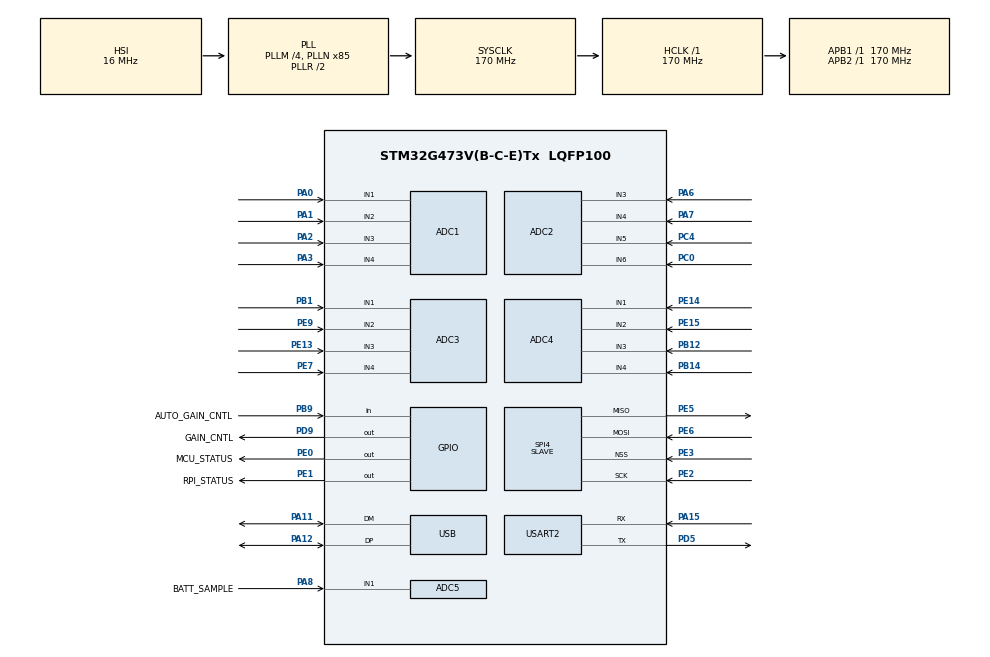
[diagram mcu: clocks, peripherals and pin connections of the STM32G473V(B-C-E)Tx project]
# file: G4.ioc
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ADC1.Channel-2\#ChannelRegularConversion=ADC_CHANNEL_1
ADC1.Channel-3\#ChannelRegularConversion=ADC_CHANNEL_2
ADC1.Channel-4\#ChannelRegularConversion=ADC_CHANNEL_3
ADC1.Channel-5\#ChannelRegularConversion=ADC_CHANNEL_4
ADC1.ContinuousConvMode=DISABLE
ADC1.DMAContinuousRequests=ENABLE
ADC1.ExternalTrigConv=ADC_EXTERNALTRIG_T6_TRGO
ADC1.NbrOfConversion=4
ADC1.NbrOfConversionFlag=1
ADC1.OffsetNumber-2\#ChannelRegularConversion=ADC_OFFSET_NONE
ADC1.OffsetNumber-3\#ChannelRegularConversion=ADC_OFFSET_NONE
ADC1.OffsetNumber-4\#ChannelRegularConversion=ADC_OFFSET_NONE
ADC1.OffsetNumber-5\#ChannelRegularConversion=ADC_OFFSET_NONE
ADC1.Overrun=ADC_OVR_DATA_OVERWRITTEN
ADC1.Rank-2\#ChannelRegularConversion=1
ADC1.Rank-3\#ChannelRegularConversion=2
ADC1.Rank-4\#ChannelRegularConversion=3
ADC1.Rank-5\#ChannelRegularConversion=4
ADC1.SamplingTime-2\#ChannelRegularConversion=ADC_SAMPLETIME_12CYCLES_5
ADC1.SamplingTime-3\#ChannelRegularConversion=ADC_SAMPLETIME_12CYCLES_5
ADC1.SamplingTime-4\#ChannelRegularConversion=ADC_SAMPLETIME_12CYCLES_5
ADC1.SamplingTime-5\#ChannelRegularConversion=ADC_SAMPLETIME_12CYCLES_5
ADC1.master=1
ADC2.Channel-0\#ChannelRegularConversion=ADC_CHANNEL_3
ADC2.Channel-1\#ChannelRegularConversion=ADC_CHANNEL_4
ADC2.Channel-2\#ChannelRegularConversion=ADC_CHANNEL_5
ADC2.Channel-3\#ChannelRegularConversion=ADC_CHANNEL_6
ADC2.ContinuousConvMode=DISABLE
ADC2.DMAContinuousRequests=ENABLE
ADC2.ExternalTrigConv=ADC_EXTERNALTRIG_T6_TRGO
ADC2.NbrOfConversion=4
ADC2.NbrOfConversionFlag=1
ADC2.OffsetNumber-0\#ChannelRegularConversion=ADC_OFFSET_NONE
ADC2.OffsetNumber-1\#ChannelRegularConversion=ADC_OFFSET_NONE
ADC2.OffsetNumber-2\#ChannelRegularConversion=ADC_OFFSET_NONE
ADC2.OffsetNumber-3\#ChannelRegularConversion=ADC_OFFSET_NONE
ADC2.Overrun=ADC_OVR_DATA_OVERWRITTEN
ADC2.Rank-0\#ChannelRegularConversion=1
ADC2.Rank-1\#ChannelRegularConversion=2
ADC2.Rank-2\#ChannelRegularConversion=3
ADC2.Rank-3\#ChannelRegularConversion=4
ADC2.SamplingTime-0\#ChannelRegularConversion=ADC_SAMPLETIME_12CYCLES_5
ADC2.SamplingTime-1\#ChannelRegularConversion=ADC_SAMPLETIME_12CYCLES_5
ADC2.SamplingTime-2\#ChannelRegularConversion=ADC_SAMPLETIME_12CYCLES_5
ADC2.SamplingTime-3\#ChannelRegularConversion=ADC_SAMPLETIME_12CYCLES_5
ADC3.Channel-0\#ChannelRegularConversion=ADC_CHANNEL_1
ADC3.Channel-1\#ChannelRegularConversion=ADC_CHANNEL_2
ADC3.Channel-2\#ChannelRegularConversion=ADC_CHANNEL_3
ADC3.Channel-3\#ChannelRegularConversion=ADC_CHANNEL_4
ADC3.ContinuousConvMode=DISABLE
ADC3.DMAContinuousRequests=ENABLE
ADC3.ExternalTrigConv=ADC_EXTERNALTRIG_T6_TRGO
ADC3.NbrOfConversion=4
ADC3.NbrOfConversionFlag=1
ADC3.OffsetNumber-0\#ChannelRegularConversion=ADC_OFFSET_NONE
ADC3.OffsetNumber-1\#ChannelRegularConversion=ADC_OFFSET_NONE
ADC3.OffsetNumber-2\#ChannelRegularConversion=ADC_OFFSET_NONE
ADC3.OffsetNumber-3\#ChannelRegularConversion=ADC_OFFSET_NONE
ADC3.Overrun=ADC_OVR_DATA_OVERWRITTEN
ADC3.Rank-0\#ChannelRegularConversion=1
ADC3.Rank-1\#ChannelRegularConversion=2
ADC3.Rank-2\#ChannelRegularConversion=3
ADC3.Rank-3\#ChannelRegularConversion=4
ADC3.SamplingTime-0\#ChannelRegularConversion=ADC_SAMPLETIME_12CYCLES_5
ADC3.SamplingTime-1\#ChannelRegularConversion=ADC_SAMPLETIME_12CYCLES_5
ADC3.SamplingTime-2\#ChannelRegularConversion=ADC_SAMPLETIME_12CYCLES_5
ADC3.SamplingTime-3\#ChannelRegularConversion=ADC_SAMPLETIME_12CYCLES_5
ADC3.master=1
ADC4.Channel-0\#ChannelRegularConversion=ADC_CHANNEL_1
ADC4.Channel-1\#ChannelRegularConversion=ADC_CHANNEL_2
ADC4.Channel-2\#ChannelRegularConversion=ADC_CHANNEL_3
ADC4.Channel-3\#ChannelRegularConversion=ADC_CHANNEL_4
ADC4.ContinuousConvMode=DISABLE
ADC4.DMAContinuousRequests=ENABLE
ADC4.EnableAnalogWatchDog1=false
ADC4.ExternalTrigConv=ADC_EXTERNALTRIG_T6_TRGO
ADC4.NbrOfConversion=4
ADC4.NbrOfConversionFlag=1
ADC4.OffsetNumber-0\#ChannelRegularConversion=ADC_OFFSET_NONE
ADC4.OffsetNumber-1\#ChannelRegularConversion=ADC_OFFSET_NONE
ADC4.OffsetNumber-2\#ChannelRegularConversion=ADC_OFFSET_NONE
ADC4.OffsetNumber-3\#ChannelRegularConversion=ADC_OFFSET_NONE
ADC4.Overrun=ADC_OVR_DATA_OVERWRITTEN
ADC4.Rank-0\#ChannelRegularConversion=1
ADC4.Rank-1\#ChannelRegularConversion=2
ADC4.Rank-2\#ChannelRegularConversion=3
ADC4.Rank-3\#ChannelRegularConversion=4
ADC4.SamplingTime-0\#ChannelRegularConversion=ADC_SAMPLETIME_12CYCLES_5
ADC4.SamplingTime-1\#ChannelRegularConversion=ADC_SAMPLETIME_12CYCLES_5
ADC4.SamplingTime-2\#ChannelRegularConversion=ADC_SAMPLETIME_12CYCLES_5
ADC4.SamplingTime-3\#ChannelRegularConversion=ADC_SAMPLETIME_12CYCLES_5
ADC5.Channel-4\#ChannelRegularConversion=ADC_CHANNEL_1
ADC5.NbrOfConversionFlag=1
ADC5.OffsetNumber-4\#ChannelRegularConversion=ADC_OFFSET_NONE
ADC5.Rank-4\#ChannelRegularConversion=1
ADC5.SamplingTime-4\#ChannelRegularConversion=ADC_SAMPLETIME_2CYCLES_5
Dma.ADC1.0.Direction=DMA_PERIPH_TO_MEMORY
Dma.ADC1.0.EventEnable=DISABLE
Dma.ADC1.0.Instance=DMA1_Channel1
Dma.ADC1.0.MemDataAlignment=DMA_MDATAALIGN_HALFWORD
Dma.ADC1.0.MemInc=DMA_MINC_ENABLE
Dma.ADC1.0.Mode=DMA_CIRCULAR
Dma.ADC1.0.PeriphDataAlignment=DMA_PDATAALIGN_HALFWORD
Dma.ADC1.0.PeriphInc=DMA_PINC_DISABLE
Dma.ADC1.0.Polarity=HAL_DMAMUX_REQ_GEN_RISING
Dma.ADC1.0.Priority=DMA_PRIORITY_LOW
Dma.ADC1.0.RequestNumber=1
Dma.ADC1.0.SignalID=NONE
Dma.ADC1.0.SyncEnable=DISABLE
Dma.ADC1.0.SyncPolarity=HAL_DMAMUX_SYNC_NO_EVENT
Dma.ADC1.0.SyncRequestNumber=1
Dma.ADC1.0.SyncSignalID=NONE
Dma.ADC2.1.Direction=DMA_PERIPH_TO_MEMORY
Dma.ADC2.1.EventEnable=DISABLE
Dma.ADC2.1.Instance=DMA1_Channel2
Dma.ADC2.1.MemDataAlignment=DMA_MDATAALIGN_HALFWORD
Dma.ADC2.1.MemInc=DMA_MINC_ENABLE
Dma.ADC2.1.Mode=DMA_CIRCULAR
Dma.ADC2.1.PeriphDataAlignment=DMA_PDATAALIGN_HALFWORD
Dma.ADC2.1.PeriphInc=DMA_PINC_DISABLE
Dma.ADC2.1.Polarity=HAL_DMAMUX_REQ_GEN_RISING
Dma.ADC2.1.Priority=DMA_PRIORITY_LOW
Dma.ADC2.1.RequestNumber=1
Dma.ADC2.1.SignalID=NONE
Dma.ADC2.1.SyncEnable=DISABLE
Dma.ADC2.1.SyncPolarity=HAL_DMAMUX_SYNC_NO_EVENT
Dma.ADC2.1.SyncRequestNumber=1
Dma.ADC2.1.SyncSignalID=NONE
Dma.ADC3.2.Direction=DMA_PERIPH_TO_MEMORY
Dma.ADC3.2.EventEnable=DISABLE
Dma.ADC3.2.Instance=DMA1_Channel3
Dma.ADC3.2.MemDataAlignment=DMA_MDATAALIGN_HALFWORD
Dma.ADC3.2.MemInc=DMA_MINC_ENABLE
Dma.ADC3.2.Mode=DMA_CIRCULAR
Dma.ADC3.2.PeriphDataAlignment=DMA_PDATAALIGN_HALFWORD
Dma.ADC3.2.PeriphInc=DMA_PINC_DISABLE
Dma.ADC3.2.Polarity=HAL_DMAMUX_REQ_GEN_RISING
Dma.ADC3.2.Priority=DMA_PRIORITY_LOW
Dma.ADC3.2.RequestNumber=1
Dma.ADC3.2.SignalID=NONE
Dma.ADC3.2.SyncEnable=DISABLE
Dma.ADC3.2.SyncPolarity=HAL_DMAMUX_SYNC_NO_EVENT
Dma.ADC3.2.SyncRequestNumber=1
Dma.ADC3.2.SyncSignalID=NONE
Dma.ADC4.3.Direction=DMA_PERIPH_TO_MEMORY
Dma.ADC4.3.EventEnable=DISABLE
Dma.ADC4.3.Instance=DMA1_Channel4
Dma.ADC4.3.MemDataAlignment=DMA_MDATAALIGN_HALFWORD
Dma.ADC4.3.MemInc=DMA_MINC_ENABLE
Dma.ADC4.3.Mode=DMA_CIRCULAR
Dma.ADC4.3.PeriphDataAlignment=DMA_PDATAALIGN_HALFWORD
Dma.ADC4.3.PeriphInc=DMA_PINC_DISABLE
Dma.ADC4.3.Polarity=HAL_DMAMUX_REQ_GEN_RISING
Dma.ADC4.3.Priority=DMA_PRIORITY_LOW
Dma.ADC4.3.RequestNumber=1
Dma.ADC4.3.SignalID=NONE
Dma.ADC4.3.SyncEnable=DISABLE
Dma.ADC4.3.SyncPolarity=HAL_DMAMUX_SYNC_NO_EVENT
Dma.ADC4.3.SyncRequestNumber=1
Dma.ADC4.3.SyncSignalID=NONE
Dma.Request0=ADC1
Dma.Request1=ADC2
Dma.Request2=ADC3
Dma.Request3=ADC4
Dma.Request4=SPI4_TX
Dma.Request5=SPI4_RX
Dma.SPI4_RX.5.Direction=DMA_PERIPH_TO_MEMORY
Dma.SPI4_RX.5.EventEnable=DISABLE
Dma.SPI4_RX.5.Instance=DMA2_Channel2
Dma.SPI4_RX.5.MemDataAlignment=DMA_MDATAALIGN_BYTE
Dma.SPI4_RX.5.MemInc=DMA_MINC_ENABLE
Dma.SPI4_RX.5.Mode=DMA_NORMAL
Dma.SPI4_RX.5.PeriphDataAlignment=DMA_PDATAALIGN_BYTE
Dma.SPI4_RX.5.PeriphInc=DMA_PINC_DISABLE
Dma.SPI4_RX.5.Polarity=HAL_DMAMUX_REQ_GEN_RISING
Dma.SPI4_RX.5.Priority=DMA_PRIORITY_HIGH
Dma.SPI4_RX.5.RequestNumber=1
Dma.SPI4_RX.5.SignalID=NONE
Dma.SPI4_RX.5.SyncEnable=DISABLE
Dma.SPI4_RX.5.SyncPolarity=HAL_DMAMUX_SYNC_NO_EVENT
Dma.SPI4_RX.5.SyncRequestNumber=1
Dma.SPI4_RX.5.SyncSignalID=NONE
Dma.SPI4_TX.4.Direction=DMA_MEMORY_TO_PERIPH
Dma.SPI4_TX.4.EventEnable=DISABLE
Dma.SPI4_TX.4.Instance=DMA2_Channel1
Dma.SPI4_TX.4.MemDataAlignment=DMA_MDATAALIGN_BYTE
Dma.SPI4_TX.4.MemInc=DMA_MINC_ENABLE
Dma.SPI4_TX.4.Mode=DMA_NORMAL
Dma.SPI4_TX.4.PeriphDataAlignment=DMA_PDATAALIGN_BYTE
Dma.SPI4_TX.4.PeriphInc=DMA_PINC_DISABLE
Dma.SPI4_TX.4.Polarity=HAL_DMAMUX_REQ_GEN_RISING
Dma.SPI4_TX.4.Priority=DMA_PRIORITY_HIGH
Dma.SPI4_TX.4.RequestNumber=1
Dma.SPI4_TX.4.SignalID=NONE
Dma.SPI4_TX.4.SyncEnable=DISABLE
Dma.SPI4_TX.4.SyncPolarity=HAL_DMAMUX_SYNC_NO_EVENT
Dma.SPI4_TX.4.SyncRequestNumber=1
Dma.SPI4_TX.4.SyncSignalID=NONE
Mcu.Family=STM32G4
Mcu.Name=STM32G473V(B-C-E)Tx
Mcu.Package=LQFP100
NVIC.ADC1_2_IRQn=true\:0\:0\:false\:false\:true\:true\:true\:true
NVIC.ADC3_IRQn=true\:0\:0\:false\:false\:true\:true\:true\:true
NVIC.ADC4_IRQn=true\:0\:0\:false\:false\:true\:true\:true\:true
NVIC.DMA1_Channel1_IRQn=true\:0\:0\:false\:false\:true\:false\:true\:true
NVIC.DMA1_Channel2_IRQn=true\:0\:0\:false\:false\:true\:false\:true\:true
NVIC.DMA1_Channel3_IRQn=true\:0\:0\:false\:false\:true\:false\:true\:true
NVIC.DMA1_Channel4_IRQn=true\:0\:0\:false\:false\:true\:false\:true\:true
NVIC.DMA2_Channel1_IRQn=true\:0\:0\:false\:false\:true\:false\:true\:true
NVIC.DMA2_Channel2_IRQn=true\:0\:0\:false\:false\:true\:false\:true\:true
NVIC.PriorityGroup=NVIC_PRIORITYGROUP_4
NVIC.SPI4_IRQn=true\:0\:0\:false\:false\:true\:true\:true\:true
NVIC.TIM6_DAC_IRQn=true\:0\:0\:false\:false\:true\:true\:true\:true
NVIC.USB_LP_IRQn=true\:0\:0\:false\:false\:true\:false\:true\:true
PA0.Mode=IN1-Single-Ended
PA0.Signal=ADC1_IN1
PA1.Mode=IN2-Single-Ended
PA1.Signal=ADC1_IN2
PA11.Mode=Device
PA11.Signal=USB_DM
PA12.Mode=Device
PA12.Signal=USB_DP
PA13.Mode=Serial_Wire
PA13.Signal=SYS_JTMS-SWDIO
PA14.Mode=Serial_Wire
PA14.Signal=SYS_JTCK-SWCLK
PA15.Mode=Asynchronous
PA15.Signal=USART2_RX
PA2.Mode=IN3-Single-Ended
PA2.Signal=ADC1_IN3
PA3.Mode=IN4-Single-Ended
PA3.Signal=ADC1_IN4
PA6.Mode=IN3-Single-Ended
PA6.Signal=ADC2_IN3
PA7.Mode=IN4-Single-Ended
PA7.Signal=ADC2_IN4
PA8.GPIO_Label=BATT_SAMPLE
PA8.Mode=IN1-Single-Ended
PA8.Signal=ADC5_IN1
PB1.Mode=IN1-Single-Ended
PB1.Signal=ADC3_IN1
PB12.Mode=IN3-Single-Ended
PB12.Signal=ADC4_IN3
PB14.Mode=IN4-Single-Ended
PB14.Signal=ADC4_IN4
PB9.GPIO_Label=AUTO_GAIN_CNTL
PB9.GPIO_PuPd=GPIO_PULLDOWN
PB9.Signal=GPIO_Input
PC0.Mode=IN6-Single-Ended
PC0.Signal=ADC2_IN6
PC4.Mode=IN5-Single-Ended
PC4.Signal=ADC2_IN5
PD5.Mode=Asynchronous
PD5.Signal=USART2_TX
PD9.GPIO_Label=GAIN_CNTL
PD9.GPIO_Speed=GPIO_SPEED_FREQ_HIGH
PD9.PinState=GPIO_PIN_RESET
PD9.Signal=GPIO_Output
PE0.GPIO_Label=MCU_STATUS
PE0.GPIO_Speed=GPIO_SPEED_FREQ_HIGH
PE0.Signal=GPIO_Output
PE1.GPIO_Label=RPI_STATUS
PE1.GPIO_Speed=GPIO_SPEED_FREQ_HIGH
PE1.Signal=GPIO_Output
PE13.Mode=IN3-Single-Ended
PE13.Signal=ADC3_IN3
PE14.Mode=IN1-Single-Ended
PE14.Signal=ADC4_IN1
PE15.Mode=IN2-Single-Ended
PE15.Signal=ADC4_IN2
PE2.GPIO_Speed=GPIO_SPEED_FREQ_VERY_HIGH
PE2.Mode=Full_Duplex_Slave
PE2.Signal=SPI4_SCK
PE3.GPIO_Speed=GPIO_SPEED_FREQ_VERY_HIGH
PE3.Mode=NSS_Signal_Hard_Input
PE3.Signal=SPI4_NSS
PE5.GPIO_Speed=GPIO_SPEED_FREQ_VERY_HIGH
PE5.Mode=Full_Duplex_Slave
PE5.Signal=SPI4_MISO
PE6.GPIO_Speed=GPIO_SPEED_FREQ_VERY_HIGH
PE6.Mode=Full_Duplex_Slave
PE6.Signal=SPI4_MOSI
PE7.Mode=IN4-Single-Ended
PE7.Signal=ADC3_IN4
PE9.Mode=IN2-Single-Ended
PE9.Signal=ADC3_IN2
ProjectManager.HeapSize=0x200
ProjectManager.StackSize=0x400
ProjectManager.TargetToolchain=STM32CubeIDE
RCC.ADC12Freq_Value=170000000
RCC.ADC345Freq_Value=170000000
RCC.AHBFreq_Value=170000000
RCC.APB1Freq_Value=170000000
RCC.APB1TimFreq_Value=170000000
RCC.APB2Freq_Value=170000000
RCC.APB2TimFreq_Value=170000000
RCC.CK48CLockSelection=RCC_USBCLKSOURCE_HSI48
RCC.CortexFreq_Value=170000000
RCC.EXTERNAL_CLOCK_VALUE=12288000
RCC.HCLKFreq_Value=170000000
RCC.HSE_VALUE=8000000
RCC.HSI48_VALUE=48000000
RCC.HSI_VALUE=16000000
RCC.LSE_VALUE=32768
RCC.PLLM=RCC_PLLM_DIV4
RCC.PLLN=85
RCC.PLLQ=RCC_PLLQ_DIV4
RCC.SYSCLKFreq_VALUE=170000000
RCC.SYSCLKSource=RCC_SYSCLKSOURCE_PLLCLK
RCC.USBFreq_Value=48000000
RCC.VCOOutputFreq_Value=340000000
SPI4.DataSize=SPI_DATASIZE_8BIT
SPI4.Direction=SPI_DIRECTION_2LINES
SPI4.Mode=SPI_MODE_SLAVE
SPI4.VirtualNSS=VM_NSSHARD
SPI4.VirtualType=VM_SLAVE
SYS.VoltageScaling=SYSCFG_VREFBUF_VOLTAGE_SCALE2
TIM6.PeriodNoDither=99
TIM6.Prescaler=16
TIM6.TIM_MasterOutputTrigger=TIM_TRGO_UPDATE
USART2.VirtualMode-Asynchronous=VM_ASYNC
USB_DEVICE.CLASS_NAME_FS=CDC
USB_DEVICE.VirtualMode=Cdc
USB_DEVICE.VirtualModeFS=Cdc_FS
VP_SYS_VS_DBSignals.Mode=DisableDeadBatterySignals
VP_TIM6_VS_ClockSourceINT.Mode=Enable_Timer
VP_USB_DEVICE_VS_USB_DEVICE_CDC_FS.Mode=CDC_FS
VREF+.Mode=InternalMode
VREF+.Signal=VREFBUF_OUT
board=custom

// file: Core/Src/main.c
/* USER CODE BEGIN Header */
/**
  ******************************************************************************
  * @file           : main.c
  * @brief          : Main program body
  ******************************************************************************
  * @attention
  *
  * Copyright (c) 2026 STMicroelectronics.
  * All rights reserved.
  *
  * This software is licensed under terms that can be found in the LICENSE file
  * in the root directory of this software component.
  * If no LICENSE file comes with this software, it is provided AS-IS.
  *
  ******************************************************************************
  */
/* USER CODE END Header */
#include "main.h"
#include "adc.h"
#include "dma.h"
#include "spi.h"
#include "tim.h"
#include "usart.h"
#include "usb_device.h"
#include "gpio.h"

/* USER CODE BEGIN Includes */
#include "app_main.h"
/* USER CODE END Includes */

void SystemClock_Config(void);

/* USER CODE BEGIN 0 */

// HAL_SYSCFG_VREFBUF_HighImpedanceConfig(SYSCFG_VREFBUF_HIGH_IMPEDANCE_DISABLE);
// HAL_SYSCFG_EnableVREFBUF();
// IMPORTANT FOR ADC VALUES, DO NOT CHANGE
//C:\Users\Fabz\Desktop\aroundfuckin\Capstone_490_Software\src\firmware\STM32G4_Cap\src\CubeMX\Core\Src\stm32g4xx_hal_msp.c

/* USER CODE END 0 */

int main(void)
{

  /* MCU Configuration--------------------------------------------------------*/

  /* Reset of all peripherals, Initializes the Flash interface and the Systick. */
  HAL_Init();

  /* Configure the system clock */
  SystemClock_Config();

  /* USER CODE BEGIN SysInit */
  // TODO: TEST the UART and USB init
  /* USER CODE END SysInit */

  /* Initialize all configured peripherals */
  MX_GPIO_Init();
  MX_DMA_Init();
  MX_ADC1_Init();
  MX_ADC2_Init();
  MX_ADC3_Init();
  MX_ADC4_Init();
  MX_SPI4_Init();
  MX_TIM6_Init();
  MX_USART2_UART_Init();
  MX_USB_Device_Init();
  MX_ADC5_Init();
  /* USER CODE BEGIN 2 */
  app_init();
  app_start();
  /* USER CODE END 2 */

  /* Infinite loop */
  while (1)
  {

    /* USER CODE BEGIN 3 */
#if MODE == RELEASE | MODE == DEBUG
    app_loop();
#elif MODE == TEST_SPI_STREAM
    test_spi_stream_loop();
#elif MODE == TEST_DSP_PIPELINE
    test_dsp_pipeline_loop();
#endif
  }

  /* USER CODE END 3 */
}

void SystemClock_Config(void)
{
  RCC_OscInitTypeDef RCC_OscInitStruct = {0};
  RCC_ClkInitTypeDef RCC_ClkInitStruct = {0};

  /** Configure the main internal regulator output voltage
  */
  HAL_PWREx_ControlVoltageScaling(PWR_REGULATOR_VOLTAGE_SCALE1_BOOST);

  /** Initializes the RCC Oscillators according to the specified parameters
  * in the RCC_OscInitTypeDef structure.
  */
  RCC_OscInitStruct.OscillatorType = RCC_OSCILLATORTYPE_HSI|RCC_OSCILLATORTYPE_HSI48;
  RCC_OscInitStruct.HSIState = RCC_HSI_ON;
  RCC_OscInitStruct.HSICalibrationValue = RCC_HSICALIBRATION_DEFAULT;
  RCC_OscInitStruct.HSI48State = RCC_HSI48_ON;
  RCC_OscInitStruct.PLL.PLLState = RCC_PLL_ON;
  RCC_OscInitStruct.PLL.PLLSource = RCC_PLLSOURCE_HSI;
  RCC_OscInitStruct.PLL.PLLM = RCC_PLLM_DIV4;
  RCC_OscInitStruct.PLL.PLLN = 85;
  RCC_OscInitStruct.PLL.PLLP = RCC_PLLP_DIV2;
  RCC_OscInitStruct.PLL.PLLQ = RCC_PLLQ_DIV4;
  RCC_OscInitStruct.PLL.PLLR = RCC_PLLR_DIV2;
  if (HAL_RCC_OscConfig(&RCC_OscInitStruct) != HAL_OK)
  {
    Error_Handler();
  }

  /** Initializes the CPU, AHB and APB buses clocks
  */
  RCC_ClkInitStruct.ClockType = RCC_CLOCKTYPE_HCLK|RCC_CLOCKTYPE_SYSCLK
                              |RCC_CLOCKTYPE_PCLK1|RCC_CLOCKTYPE_PCLK2;
  RCC_ClkInitStruct.SYSCLKSource = RCC_SYSCLKSOURCE_PLLCLK;
  RCC_ClkInitStruct.AHBCLKDivider = RCC_SYSCLK_DIV1;
  RCC_ClkInitStruct.APB1CLKDivider = RCC_HCLK_DIV1;
  RCC_ClkInitStruct.APB2CLKDivider = RCC_HCLK_DIV1;

  if (HAL_RCC_ClockConfig(&RCC_ClkInitStruct, FLASH_LATENCY_4) != HAL_OK)
  {
    Error_Handler();
  }
}

void Error_Handler(void)
{
  __disable_irq();
  while (1)
  {
  }
}
